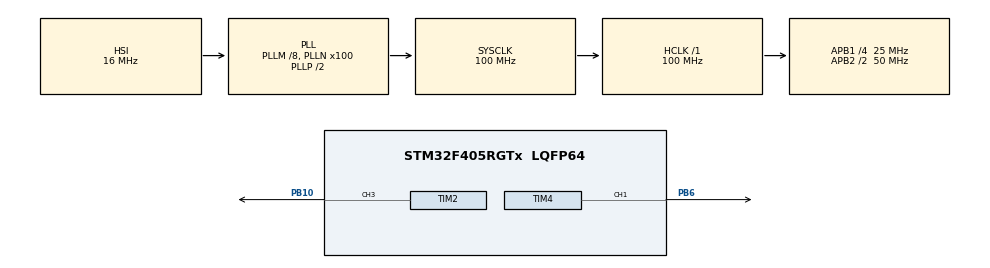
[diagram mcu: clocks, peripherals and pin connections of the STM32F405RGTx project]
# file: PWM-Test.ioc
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Mcu.Family=STM32F4
Mcu.Name=STM32F405RGTx
Mcu.Package=LQFP64
NVIC.PriorityGroup=NVIC_PRIORITYGROUP_4
PB10.Signal=S_TIM2_CH3
PB6.Signal=S_TIM4_CH1
PH0-OSC_IN.Mode=HSE-External-Oscillator
PH0-OSC_IN.Signal=RCC_OSC_IN
PH1-OSC_OUT.Mode=HSE-External-Oscillator
PH1-OSC_OUT.Signal=RCC_OSC_OUT
ProjectManager.HeapSize=0x200
ProjectManager.StackSize=0x400
ProjectManager.TargetToolchain=STM32CubeIDE
RCC.48MHZClocksFreq_Value=50000000
RCC.AHBFreq_Value=100000000
RCC.APB1CLKDivider=RCC_HCLK_DIV4
RCC.APB1Freq_Value=25000000
RCC.APB1TimFreq_Value=50000000
RCC.APB2CLKDivider=RCC_HCLK_DIV2
RCC.APB2Freq_Value=50000000
RCC.APB2TimFreq_Value=100000000
RCC.CortexFreq_Value=100000000
RCC.HCLKFreq_Value=100000000
RCC.HSE_VALUE=8000000
RCC.HSI_VALUE=16000000
RCC.LSE_VALUE=32768
RCC.PLLM=8
RCC.PLLN=100
RCC.SYSCLKFreq_VALUE=100000000
RCC.SYSCLKSource=RCC_SYSCLKSOURCE_PLLCLK
RCC.VCOOutputFreq_Value=200000000
SH.S_TIM2_CH3.0=TIM2_CH3,PWM Generation3 CH3
SH.S_TIM4_CH1.0=TIM4_CH1,PWM Generation1 CH1
TIM2.Channel-PWM\ Generation3\ CH3=TIM_CHANNEL_3
TIM2.Period=19-1
TIM2.Prescaler=9
TIM2.Pulse-PWM\ Generation3\ CH3=10
TIM4.Channel-PWM\ Generation1\ CH1=TIM_CHANNEL_1
TIM4.Period=19-1
TIM4.Prescaler=9
TIM4.Pulse-PWM\ Generation1\ CH1=10
VP_TIM2_VS_ClockSourceINT.Mode=Internal
VP_TIM4_VS_ClockSourceINT.Mode=Internal
board=custom

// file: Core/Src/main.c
/* USER CODE BEGIN Header */
/**
  ******************************************************************************
  * @file           : main.c
  * @brief          : Main program body
  ******************************************************************************
  * @attention
  *
  * <h2><center>&copy; Copyright (c) 2020 STMicroelectronics.
  * All rights reserved.</center></h2>
  *
  * This software component is licensed by ST under BSD 3-Clause license,
  * the "License"; You may not use this file except in compliance with the
  * License. You may obtain a copy of the License at:
  *                        opensource.org/licenses/BSD-3-Clause
  *
  ******************************************************************************
  */
/* USER CODE END Header */

#include "main.h"

TIM_HandleTypeDef htim2;
TIM_HandleTypeDef htim4;

void SystemClock_Config(void);
static void MX_GPIO_Init(void);
static void MX_TIM2_Init(void);
static void MX_TIM4_Init(void);

int main(void)
{

  /* MCU Configuration--------------------------------------------------------*/

  /* Reset of all peripherals, Initializes the Flash interface and the Systick. */
  HAL_Init();

  /* Configure the system clock */
  SystemClock_Config();

  /* Initialize all configured peripherals */
  MX_GPIO_Init();
  MX_TIM2_Init();
  MX_TIM4_Init();
  /* USER CODE BEGIN 2 */
  HAL_TIM_PWM_Start(&htim2, TIM_CHANNEL_3);  //Start PWM
  HAL_TIM_PWM_Start(&htim4, TIM_CHANNEL_1);  //Start PWM
  /* USER CODE END 2 */

  /* Infinite loop */
  while (1)
  {

  }
}

void SystemClock_Config(void)
{
  RCC_OscInitTypeDef RCC_OscInitStruct = {0};
  RCC_ClkInitTypeDef RCC_ClkInitStruct = {0};

  /** Configure the main internal regulator output voltage
  */
  __HAL_RCC_PWR_CLK_ENABLE();
  __HAL_PWR_VOLTAGESCALING_CONFIG(PWR_REGULATOR_VOLTAGE_SCALE1);
  /** Initializes the CPU, AHB and APB busses clocks
  */
  RCC_OscInitStruct.OscillatorType = RCC_OSCILLATORTYPE_HSI;
  RCC_OscInitStruct.HSIState = RCC_HSI_ON;
  RCC_OscInitStruct.HSICalibrationValue = RCC_HSICALIBRATION_DEFAULT;
  RCC_OscInitStruct.PLL.PLLState = RCC_PLL_ON;
  RCC_OscInitStruct.PLL.PLLSource = RCC_PLLSOURCE_HSI;
  RCC_OscInitStruct.PLL.PLLM = 8;
  RCC_OscInitStruct.PLL.PLLN = 100;
  RCC_OscInitStruct.PLL.PLLP = RCC_PLLP_DIV2;
  RCC_OscInitStruct.PLL.PLLQ = 4;
  if (HAL_RCC_OscConfig(&RCC_OscInitStruct) != HAL_OK)
  {
    Error_Handler();
  }
  /** Initializes the CPU, AHB and APB busses clocks
  */
  RCC_ClkInitStruct.ClockType = RCC_CLOCKTYPE_HCLK|RCC_CLOCKTYPE_SYSCLK
                              |RCC_CLOCKTYPE_PCLK1|RCC_CLOCKTYPE_PCLK2;
  RCC_ClkInitStruct.SYSCLKSource = RCC_SYSCLKSOURCE_PLLCLK;
  RCC_ClkInitStruct.AHBCLKDivider = RCC_SYSCLK_DIV1;
  RCC_ClkInitStruct.APB1CLKDivider = RCC_HCLK_DIV4;
  RCC_ClkInitStruct.APB2CLKDivider = RCC_HCLK_DIV2;

  if (HAL_RCC_ClockConfig(&RCC_ClkInitStruct, FLASH_LATENCY_3) != HAL_OK)
  {
    Error_Handler();
  }
}

static void MX_TIM2_Init(void)
{

  TIM_ClockConfigTypeDef sClockSourceConfig = {0};
  TIM_MasterConfigTypeDef sMasterConfig = {0};
  TIM_OC_InitTypeDef sConfigOC = {0};

  htim2.Instance = TIM2;
  htim2.Init.Prescaler = 9;
  htim2.Init.CounterMode = TIM_COUNTERMODE_UP;
  htim2.Init.Period = 19-1;
  htim2.Init.ClockDivision = TIM_CLOCKDIVISION_DIV1;
  htim2.Init.AutoReloadPreload = TIM_AUTORELOAD_PRELOAD_DISABLE;
  if (HAL_TIM_Base_Init(&htim2) != HAL_OK)
  {
    Error_Handler();
  }
  sClockSourceConfig.ClockSource = TIM_CLOCKSOURCE_INTERNAL;
  if (HAL_TIM_ConfigClockSource(&htim2, &sClockSourceConfig) != HAL_OK)
  {
    Error_Handler();
  }
  if (HAL_TIM_PWM_Init(&htim2) != HAL_OK)
  {
    Error_Handler();
  }
  sMasterConfig.MasterOutputTrigger = TIM_TRGO_RESET;
  sMasterConfig.MasterSlaveMode = TIM_MASTERSLAVEMODE_DISABLE;
  if (HAL_TIMEx_MasterConfigSynchronization(&htim2, &sMasterConfig) != HAL_OK)
  {
    Error_Handler();
  }
  sConfigOC.OCMode = TIM_OCMODE_PWM1;
  sConfigOC.Pulse = 10;
  sConfigOC.OCPolarity = TIM_OCPOLARITY_HIGH;
  sConfigOC.OCFastMode = TIM_OCFAST_DISABLE;
  if (HAL_TIM_PWM_ConfigChannel(&htim2, &sConfigOC, TIM_CHANNEL_3) != HAL_OK)
  {
    Error_Handler();
  }
  HAL_TIM_MspPostInit(&htim2);

}

static void MX_TIM4_Init(void)
{

  TIM_ClockConfigTypeDef sClockSourceConfig = {0};
  TIM_MasterConfigTypeDef sMasterConfig = {0};
  TIM_OC_InitTypeDef sConfigOC = {0};

  htim4.Instance = TIM4;
  htim4.Init.Prescaler = 9;
  htim4.Init.CounterMode = TIM_COUNTERMODE_UP;
  htim4.Init.Period = 19-1;
  htim4.Init.ClockDivision = TIM_CLOCKDIVISION_DIV1;
  htim4.Init.AutoReloadPreload = TIM_AUTORELOAD_PRELOAD_DISABLE;
  if (HAL_TIM_Base_Init(&htim4) != HAL_OK)
  {
    Error_Handler();
  }
  sClockSourceConfig.ClockSource = TIM_CLOCKSOURCE_INTERNAL;
  if (HAL_TIM_ConfigClockSource(&htim4, &sClockSourceConfig) != HAL_OK)
  {
    Error_Handler();
  }
  if (HAL_TIM_PWM_Init(&htim4) != HAL_OK)
  {
    Error_Handler();
  }
  sMasterConfig.MasterOutputTrigger = TIM_TRGO_RESET;
  sMasterConfig.MasterSlaveMode = TIM_MASTERSLAVEMODE_DISABLE;
  if (HAL_TIMEx_MasterConfigSynchronization(&htim4, &sMasterConfig) != HAL_OK)
  {
    Error_Handler();
  }
  sConfigOC.OCMode = TIM_OCMODE_PWM1;
  sConfigOC.Pulse = 10;
  sConfigOC.OCPolarity = TIM_OCPOLARITY_HIGH;
  sConfigOC.OCFastMode = TIM_OCFAST_DISABLE;
  if (HAL_TIM_PWM_ConfigChannel(&htim4, &sConfigOC, TIM_CHANNEL_1) != HAL_OK)
  {
    Error_Handler();
  }
  HAL_TIM_MspPostInit(&htim4);

}

static void MX_GPIO_Init(void)
{

  /* GPIO Ports Clock Enable */
  __HAL_RCC_GPIOH_CLK_ENABLE();
  __HAL_RCC_GPIOB_CLK_ENABLE();

}

void Error_Handler(void)
{
}

/************************ (C) COPYRIGHT STMicroelectronics *****END OF FILE****/
